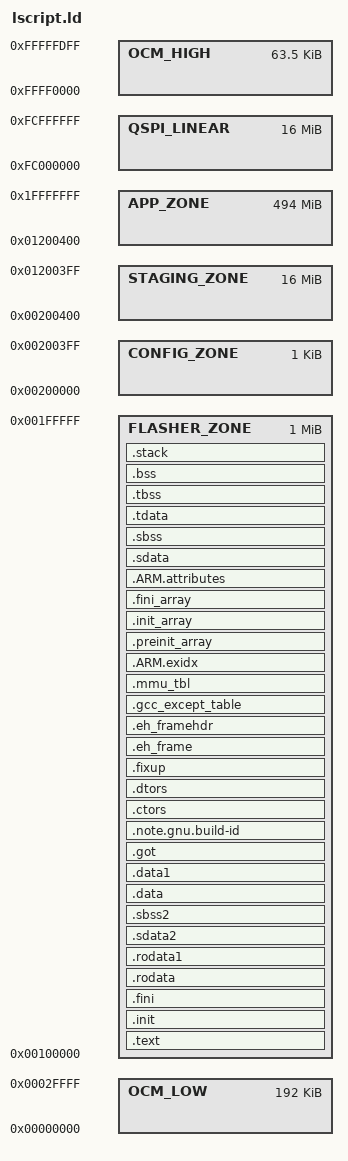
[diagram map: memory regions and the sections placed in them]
/*******************************************************************/
/*                                                                 */
/* This file is automatically generated by linker script generator.*/
/*                                                                 */
/* Version: 2018.3                                                 */
/*                                                                 */
/* Copyright (c) 2010-2019 Xilinx, Inc.  All rights reserved.      */
/*                                                                 */
/* Description : Cortex-A9 Linker Script                           */
/*                                                                 */
/*******************************************************************/

_STACK_SIZE = 0x2000;

_ABORT_STACK_SIZE = 1024;
_SUPERVISOR_STACK_SIZE = 2048;
_IRQ_STACK_SIZE = 1024;
_FIQ_STACK_SIZE = 1024;
_UNDEF_STACK_SIZE = 1024;

_STAGING_START = ORIGIN(STAGING_ZONE);
_STAGING_END   = ORIGIN(STAGING_ZONE) + LENGTH(STAGING_ZONE);

MEMORY
{
   /* On-Chip Memory Windows */
   OCM_LOW      : ORIGIN = 0x00000000, LENGTH = 0x00030000
   OCM_HIGH     : ORIGIN = 0xFFFF0000, LENGTH = 0x0000FE00

   /* QSPI Linear Mode (Read-only mapping) */
   QSPI_LINEAR  : ORIGIN = 0xFC000000, LENGTH = 0x01000000

   /* DDR Partitions */
   FLASHER_ZONE : ORIGIN = 0x00100000, LENGTH = 0x00100000 /* 1MB */
   CONFIG_ZONE  : ORIGIN = 0x00200000, LENGTH = 0x00000400 /* 1KB */
   STAGING_ZONE : ORIGIN = 0x00200400, LENGTH = 0x01000000 /* 16MB */
   APP_ZONE     : ORIGIN = 0x01200400, LENGTH = 0x1EDFFC00 /* ~494MB */
}

/* Specify the default entry point to the program */

ENTRY(_vector_table)

/* Define the sections, and where they are mapped in memory */

SECTIONS
{
.text : {
   . = ALIGN(2048);
   KEEP (*(.vectors))
   *(.boot)
   *(.text)
   *(.text.*)
   *(.gnu.linkonce.t.*)
   *(.plt)
   *(.gnu_warning)
   *(.gcc_execpt_table)
   *(.glue_7)
   *(.glue_7t)
   *(.vfp11_veneer)
   *(.ARM.extab)
   *(.gnu.linkonce.armextab.*)
} > FLASHER_ZONE

.init : {
   KEEP (*(.init))
} > FLASHER_ZONE

.fini : {
   KEEP (*(.fini))
} > FLASHER_ZONE

.rodata : {
   __rodata_start = .;
   *(.rodata)
   *(.rodata.*)
   *(.gnu.linkonce.r.*)
   __rodata_end = .;
} > FLASHER_ZONE

.rodata1 : {
   __rodata1_start = .;
   *(.rodata1)
   *(.rodata1.*)
   __rodata1_end = .;
} > FLASHER_ZONE

.sdata2 : {
   __sdata2_start = .;
   *(.sdata2)
   *(.sdata2.*)
   *(.gnu.linkonce.s2.*)
   __sdata2_end = .;
} > FLASHER_ZONE

.sbss2 : {
   __sbss2_start = .;
   *(.sbss2)
   *(.sbss2.*)
   *(.gnu.linkonce.sb2.*)
   __sbss2_end = .;
} > FLASHER_ZONE

.data : {
   __data_start = .;
   *(.data)
   *(.data.*)
   *(.gnu.linkonce.d.*)
   *(.jcr)
   *(.got)
   *(.got.plt)
   __data_end = .;
} > FLASHER_ZONE

.data1 : {
   __data1_start = .;
   *(.data1)
   *(.data1.*)
   __data1_end = .;
} > FLASHER_ZONE

.got : {
   *(.got)
} > FLASHER_ZONE

.note.gnu.build-id : {
   KEEP (*(.note.gnu.build-id))
} > FLASHER_ZONE

.ctors : {
   __CTOR_LIST__ = .;
   ___CTORS_LIST___ = .;
   KEEP (*crtbegin.o(.ctors))
   KEEP (*(EXCLUDE_FILE(*crtend.o) .ctors))
   KEEP (*(SORT(.ctors.*)))
   KEEP (*(.ctors))
   __CTOR_END__ = .;
   ___CTORS_END___ = .;
} > FLASHER_ZONE

.dtors : {
   __DTOR_LIST__ = .;
   ___DTORS_LIST___ = .;
   KEEP (*crtbegin.o(.dtors))
   KEEP (*(EXCLUDE_FILE(*crtend.o) .dtors))
   KEEP (*(SORT(.dtors.*)))
   KEEP (*(.dtors))
   __DTOR_END__ = .;
   ___DTORS_END___ = .;
} > FLASHER_ZONE

.fixup : {
   __fixup_start = .;
   *(.fixup)
   __fixup_end = .;
} > FLASHER_ZONE

.eh_frame : {
   *(.eh_frame)
} > FLASHER_ZONE

.eh_framehdr : {
   __eh_framehdr_start = .;
   *(.eh_framehdr)
   __eh_framehdr_end = .;
} > FLASHER_ZONE

.gcc_except_table : {
   *(.gcc_except_table)
} > FLASHER_ZONE

.mmu_tbl (ALIGN(16384)) : {
   __mmu_tbl_start = .;
   *(.mmu_tbl)
   __mmu_tbl_end = .;
} > FLASHER_ZONE

.ARM.exidx : {
   __exidx_start = .;
   *(.ARM.exidx*)
   *(.gnu.linkonce.armexidix.*.*)
   __exidx_end = .;
} > FLASHER_ZONE

.preinit_array : {
   __preinit_array_start = .;
   KEEP (*(SORT(.preinit_array.*)))
   KEEP (*(.preinit_array))
   __preinit_array_end = .;
} > FLASHER_ZONE

.init_array : {
   __init_array_start = .;
   KEEP (*(SORT(.init_array.*)))
   KEEP (*(.init_array))
   __init_array_end = .;
} > FLASHER_ZONE

.fini_array : {
   __fini_array_start = .;
   KEEP (*(SORT(.fini_array.*)))
   KEEP (*(.fini_array))
   __fini_array_end = .;
} > FLASHER_ZONE

.ARM.attributes : {
   __ARM.attributes_start = .;
   *(.ARM.attributes)
   __ARM.attributes_end = .;
} > FLASHER_ZONE

.sdata : {
   __sdata_start = .;
   *(.sdata)
   *(.sdata.*)
   *(.gnu.linkonce.s.*)
   __sdata_end = .;
} > FLASHER_ZONE

.sbss (NOLOAD) : {
   __sbss_start = .;
   *(.sbss)
   *(.sbss.*)
   *(.gnu.linkonce.sb.*)
   __sbss_end = .;
} > FLASHER_ZONE

.tdata : {
   __tdata_start = .;
   *(.tdata)
   *(.tdata.*)
   *(.gnu.linkonce.td.*)
   __tdata_end = .;
} > FLASHER_ZONE

.tbss : {
   __tbss_start = .;
   *(.tbss)
   *(.tbss.*)
   *(.gnu.linkonce.tb.*)
   __tbss_end = .;
} > FLASHER_ZONE

.bss (NOLOAD) : {
   __bss_start = .;
   *(.bss)
   *(.bss.*)
   *(.gnu.linkonce.b.*)
   *(COMMON)
   __bss_end = .;
} > FLASHER_ZONE

_SDA_BASE_ = __sdata_start + ((__sbss_end - __sdata_start) / 2 );

_SDA2_BASE_ = __sdata2_start + ((__sbss2_end - __sdata2_start) / 2 );

/* Generate Stack and Heap definitions */

.stack (NOLOAD) : {
   . = ALIGN(16);
   _stack_end = .;
   . += _STACK_SIZE;
   . = ALIGN(16);
   _stack = .;
   __stack = _stack;
   . = ALIGN(16);
   _irq_stack_end = .;
   . += _IRQ_STACK_SIZE;
   . = ALIGN(16);
   __irq_stack = .;
   _supervisor_stack_end = .;
   . += _SUPERVISOR_STACK_SIZE;
   . = ALIGN(16);
   __supervisor_stack = .;
   _abort_stack_end = .;
   . += _ABORT_STACK_SIZE;
   . = ALIGN(16);
   __abort_stack = .;
   _fiq_stack_end = .;
   . += _FIQ_STACK_SIZE;
   . = ALIGN(16);
   __fiq_stack = .;
   _undef_stack_end = .;
   . += _UNDEF_STACK_SIZE;
   . = ALIGN(16);
   __undef_stack = .;
} > FLASHER_ZONE

_end = .;
}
